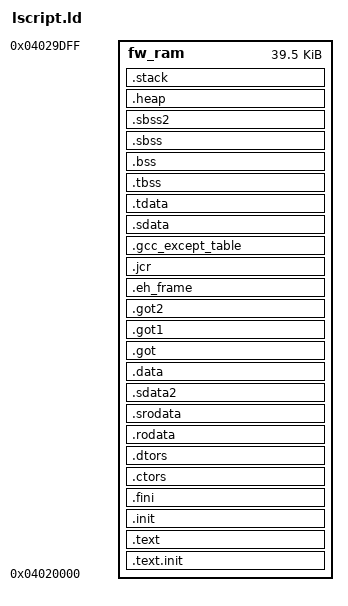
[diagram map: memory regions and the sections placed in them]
/*******************************************************************/
/*                                                                 */
/* This file is automatically generated by linker script generator.*/
/*                                                                 */
/* Version: 2018.3                                                 */
/*                                                                 */
/* Copyright (c) 2010-2019 Xilinx, Inc.  All rights reserved.      */
/*                                                                 */
/* Description : RISC-V Linker Script                           */
/*                                                                 */
/*******************************************************************/

_STACK_SIZE = DEFINED(_STACK_SIZE) ? _STACK_SIZE : 0x1000;
_HEAP_SIZE = DEFINED(_HEAP_SIZE) ? _HEAP_SIZE : 0x800;

/* Define Memories in the system */

MEMORY
{
   fw_ram : ORIGIN = 0x04020000, LENGTH = 0x9E00
}

/* Specify the default entry point to the program */

ENTRY(_boot)

/* Define the sections, and where they are mapped in memory */

SECTIONS
{
.text.init : {
   __text.init_start = .;
   *(.text.init)
   __text.init_end = .;
} > fw_ram

.text : {
   . = ALIGN(2048);
   *(.text)
   *(.text.*)
   *(.gnu.linkonce.t.*)
   *(.note.gnu.build-id)
} > fw_ram

.init : {
   KEEP (*(.init))
} > fw_ram

.fini : {
   KEEP (*(.fini))
} > fw_ram

.ctors : {
   __CTOR_LIST__ = .;
   ___CTORS_LIST___ = .;
   KEEP (*crtbegin.o(.ctors))
   KEEP (*(EXCLUDE_FILE(*crtend.o) .ctors))
   KEEP (*(SORT(.ctors.*)))
   KEEP (*(.ctors))
   __CTOR_END__ = .;
   ___CTORS_END___ = .;
} > fw_ram

.dtors : {
   __DTOR_LIST__ = .;
   ___DTORS_LIST___ = .;
   KEEP (*crtbegin.o(.dtors))
   KEEP (*(EXCLUDE_FILE(*crtend.o) .dtors))
   KEEP (*(SORT(.dtors.*)))
   KEEP (*(.dtors))
   __DTOR_END__ = .;
   ___DTORS_END___ = .;
} > fw_ram

.rodata : {
   __rodata_start = .;
   *(.rodata)
   *(.rodata.*)
   *(.gnu.linkonce.r.*)
   __rodata_end = .;
} > fw_ram

.srodata : {
   __srodata_start = .;
   *(.srodata)
   __srodata_end = .;
} > fw_ram

.sdata2 : {
   __sdata2_start = .;
   *(.sdata2)
   *(.sdata2.*)
   *(.gnu.linkonce.s2.*)
   __sdata2_end = .;
} > fw_ram

.data : {
   __data_start = .;
   *(.data)
   *(.data.*)
   *(.gnu.linkonce.d.*)
   _edata = .;
} > fw_ram

.got : {
   *(.got)
} > fw_ram

.got1 : {
   *(.got1)
} > fw_ram

.got2 : {
   *(.got2)
} > fw_ram

.eh_frame : {
   *(.eh_frame)
} > fw_ram

.jcr : {
   *(.jcr)
} > fw_ram

.gcc_except_table : {
   *(.gcc_except_table)
} > fw_ram

.sdata : {
   __sdata_start = .;
   *(.sdata)
   *(.sdata.*)
   *(.gnu.linkonce.s.*)
   __sdata_end = .;
} > fw_ram

.tdata : {
   __tdata_start = .;
   *(.tdata)
   *(.tdata.*)
   *(.gnu.linkonce.td.*)
   __tdata_end = .;
} > fw_ram

.tbss : {
   __tbss_start = .;
   *(.tbss)
   *(.tbss.*)
   *(.gnu.linkonce.tb.*)
   __tbss_end = .;
} > fw_ram

.bss (NOLOAD) : {
   __bss_start = .;
   *(.bss)
   *(.bss.*)
   *(.gnu.linkonce.b.*)
   *(COMMON)
   __bss_end = .;
} > fw_ram

.sbss (NOLOAD) : {
   __sbss_start = .;
   *(.sbss)
   *(.sbss.*)
   *(.gnu.linkonce.sb.*)
   __sbss_end = .;
} > fw_ram

.sbss2 : {
   __sbss2_start = .;
   *(.sbss2)
   *(.sbss2.*)
   *(.gnu.linkonce.sb2.*)
   __sbss2_end = .;
} > fw_ram


_SDA_BASE_ = __sdata_start + ((__sbss_end - __sdata_start) / 2 );

_SDA2_BASE_ = __sdata2_start + ((__sbss2_end - __sdata2_start) / 2 );

/* Generate Stack and Heap definitions */

.heap (NOLOAD) : {
   . = ALIGN(8);
   _heap = .;
   _heap_start = .;
   . += _HEAP_SIZE;
   _heap_end = .;
} > fw_ram

.stack (NOLOAD) : {
   _stack_end = .;
   . += _STACK_SIZE;
   . = ALIGN(8);
   _stack = .;
   __stack = _stack;
} > fw_ram

__global_pointer$ = MIN(__sdata_start + 0x800, MAX(__data_start + 0x800, __bss_end - 0x800));
_end = .;
}
